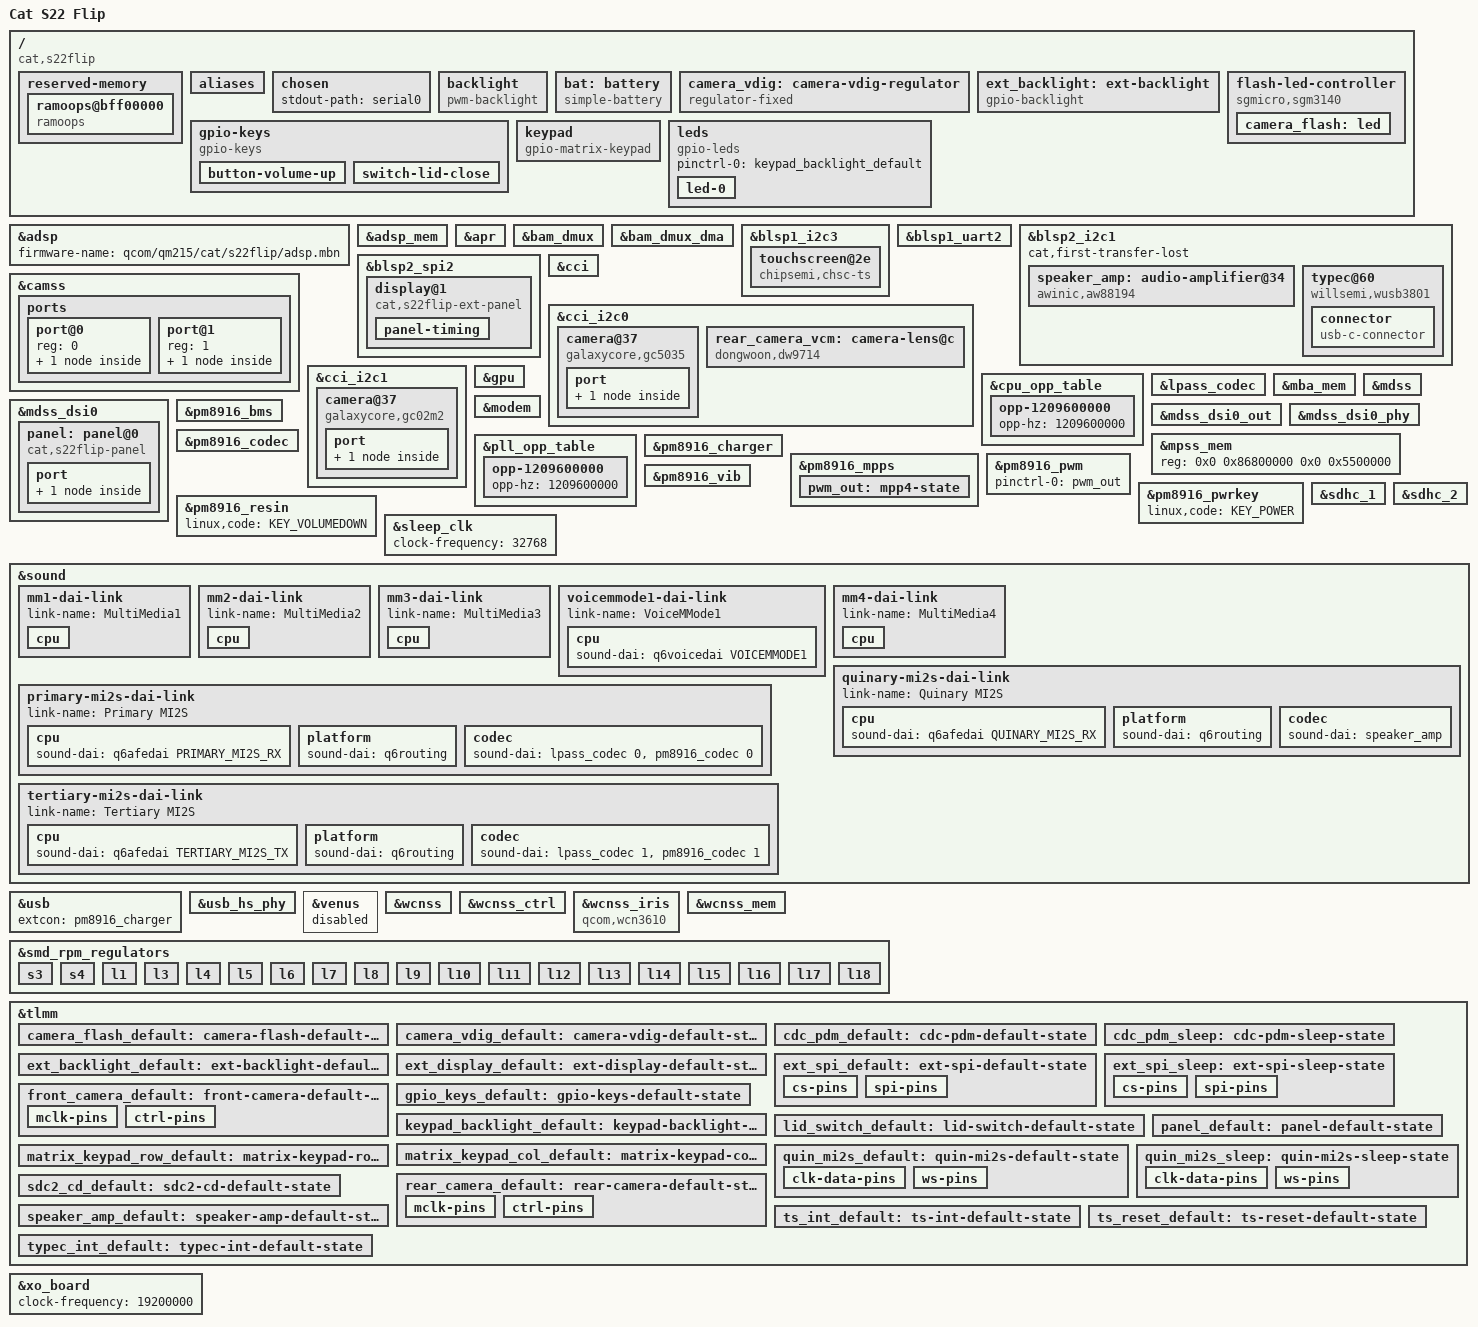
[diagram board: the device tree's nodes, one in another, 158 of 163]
// SPDX-License-Identifier: GPL-2.0-only
/*
 * Cat S22 Flip (QM215 + PM8916)
 *
 * Values marked "stock" come from the vendor device tree as running on
 * firmware LTE_S02113.11_N_S22Flip_0.030.03 (board id 12, dtbo 27).
 */

/dts-v1/;

#include "qm215-pm8916.dtsi"

#include <dt-bindings/gpio/gpio.h>
#include <dt-bindings/input/input.h>
#include <dt-bindings/interrupt-controller/irq.h>
#include <dt-bindings/leds/common.h>
#include <dt-bindings/pinctrl/qcom,pmic-mpp.h>
#include <dt-bindings/sound/qcom,q6voice.h>

/ {
	model = "Cat S22 Flip";
	compatible = "cat,s22flip", "qcom,qm215", "qcom,msm8917";
	chassis-type = "handset";

	reserved-memory {
		/*
		 * The kernel log survives a warm reset here (pstore):
		 * /sys/fs/pstore after the next boot. High in RAM, away
		 * from where the bootloaders load anything.
		 */
		ramoops@bff00000 {
			compatible = "ramoops";
			reg = <0x0 0xbff00000 0x0 0x100000>;
			record-size = <0x20000>;
			console-size = <0x40000>;
			pmsg-size = <0x20000>;
		};
	};

	aliases {
		mmc0 = &sdhc_1;
		mmc1 = &sdhc_2;
		serial0 = &blsp1_uart2;
	};

	chosen {
		stdout-path = "serial0";
	};

	/* Main display backlight: PM8916 LPG on MPP4 (stock: bl_ctrl_pwm, bank 0) */
	backlight: backlight {
		compatible = "pwm-backlight";
		pwms = <&pm8916_pwm 0 100000>;

		brightness-levels = <0 255>;
		num-interpolated-steps = <255>;
		default-brightness-level = <128>;
	};

	/* Stock battery profile "Q2805": 2000 mAh, OCV table at 25 C */
	bat: battery {
		compatible = "simple-battery";
		voltage-min-design-microvolt = <3400000>;
		/* Stock charger vddmax; the cell profile allows up to 4.35 V */
		voltage-max-design-microvolt = <4325000>;
		charge-full-design-microamp-hours = <2000000>;
		charge-term-current-microamp = <90000>;

		ocv-capacity-celsius = <25>;
		ocv-capacity-table-0 = <4318000 100>, <4246000 95>,
			<4190000 90>, <4136000 85>, <4084000 80>, <4038000 75>,
			<3982000 70>, <3952000 65>, <3912000 60>, <3866000 55>,
			<3834000 50>, <3812000 45>, <3795000 40>, <3782000 35>,
			<3772000 30>, <3763000 25>, <3756000 20>, <3739000 16>,
			<3732000 13>, <3725000 11>, <3718000 10>, <3686000 9>,
			<3684000 8>, <3682000 7>, <3676000 6>, <3654000 5>,
			<3610000 4>, <3549000 3>, <3470000 2>, <3345000 1>,
			<3000000 0>;
	};

	/*
	 * Outer display backlight. Stock drives it with a pulse-count protocol
	 * ("bl_gpio_pulse"); plain on/off is enough for now.
	 */
	/* 1.2 V for both cameras' digital cores, enabled by GPIO 25 */
	camera_vdig: camera-vdig-regulator {
		compatible = "regulator-fixed";
		regulator-name = "camera_vdig";
		regulator-min-microvolt = <1200000>;
		regulator-max-microvolt = <1200000>;
		gpio = <&tlmm 25 GPIO_ACTIVE_HIGH>;
		enable-active-high;

		pinctrl-0 = <&camera_vdig_default>;
		pinctrl-names = "default";
	};

	ext_backlight: ext-backlight {
		compatible = "gpio-backlight";
		gpios = <&tlmm 12 GPIO_ACTIVE_HIGH>;
		default-on;

		pinctrl-0 = <&ext_backlight_default>;
		pinctrl-names = "default";
	};

	/* Rear camera flash: stock "qm215-gpio-flash", enable 33, flash 34 */
	flash-led-controller {
		compatible = "sgmicro,sgm3140";
		enable-gpios = <&tlmm 33 GPIO_ACTIVE_HIGH>;
		flash-gpios = <&tlmm 34 GPIO_ACTIVE_HIGH>;

		pinctrl-0 = <&camera_flash_default>;
		pinctrl-names = "default";

		camera_flash: led {
			function = LED_FUNCTION_FLASH;
			color = <LED_COLOR_ID_WHITE>;
			flash-max-timeout-us = <250000>;
		};
	};

	gpio-keys {
		compatible = "gpio-keys";

		pinctrl-0 = <&gpio_keys_default>, <&lid_switch_default>;
		pinctrl-names = "default";

		label = "GPIO Buttons";

		button-volume-up {
			label = "Volume Up";
			gpios = <&tlmm 91 GPIO_ACTIVE_LOW>;
			linux,code = <KEY_VOLUMEUP>;
			debounce-interval = <15>;
			wakeup-source;
		};

		switch-lid-close {
			label = "Lid";
			gpios = <&tlmm 44 GPIO_ACTIVE_LOW>;
			linux,input-type = <EV_SW>;
			linux,code = <SW_LID>;
			wakeup-source;
		};
	};

	/*
	 * Stock scans this matrix active-high (no gpio-activelow): columns are
	 * driven high and a pressed key pulls its row high, so rows need
	 * pull-downs. Keycodes are the stock ones.
	 *
	 * Stock debounces for only 3 ms, but the domes chatter for up to ~35 ms
	 * after first contact (measured), producing double presses.
	 */
	keypad {
		compatible = "gpio-matrix-keypad";

		pinctrl-0 = <&matrix_keypad_row_default>, <&matrix_keypad_col_default>;
		pinctrl-names = "default";

		debounce-delay-ms = <30>;
		col-scan-delay-us = <5>;
		wakeup-source;

		row-gpios = <&tlmm 126 GPIO_ACTIVE_HIGH>,
			    <&tlmm 127 GPIO_ACTIVE_HIGH>,
			    <&tlmm 45 GPIO_ACTIVE_HIGH>,
			    <&tlmm 97 GPIO_ACTIVE_HIGH>,
			    <&tlmm 62 GPIO_ACTIVE_HIGH>;

		col-gpios = <&tlmm 96 GPIO_ACTIVE_HIGH>,
			    <&tlmm 99 GPIO_ACTIVE_HIGH>,
			    <&tlmm 90 GPIO_ACTIVE_HIGH>,
			    <&tlmm 89 GPIO_ACTIVE_HIGH>,
			    <&tlmm 129 GPIO_ACTIVE_HIGH>;

		linux,keymap = <
			MATRIX_KEY(0, 0, KEY_PHONE)
			MATRIX_KEY(0, 1, KEY_3)
			MATRIX_KEY(0, 2, KEY_6)
			MATRIX_KEY(0, 3, KEY_9)
			MATRIX_KEY(0, 4, KEY_NUMERIC_POUND)

			MATRIX_KEY(1, 0, KEY_LEFT)
			MATRIX_KEY(1, 1, KEY_2)
			MATRIX_KEY(1, 2, KEY_5)
			MATRIX_KEY(1, 3, KEY_8)
			MATRIX_KEY(1, 4, KEY_0)

			MATRIX_KEY(2, 0, KEY_MICMUTE)
			MATRIX_KEY(2, 1, KEY_1)
			MATRIX_KEY(2, 2, KEY_4)
			MATRIX_KEY(2, 3, KEY_7)
			MATRIX_KEY(2, 4, KEY_NUMERIC_STAR)

			MATRIX_KEY(3, 0, KEY_ENTER)
			MATRIX_KEY(3, 1, KEY_RIGHT)
			MATRIX_KEY(3, 2, KEY_BACKSPACE)
			MATRIX_KEY(3, 3, KEY_UP)
			MATRIX_KEY(3, 4, KEY_DOWN)

			MATRIX_KEY(4, 0, KEY_BACK)
			MATRIX_KEY(4, 1, KEY_APPSELECT)
			MATRIX_KEY(4, 2, KEY_HOMEPAGE)
			MATRIX_KEY(4, 3, KEY_NUMERIC_B)
			MATRIX_KEY(4, 4, KEY_NUMERIC_A)
		>;
	};

	leds {
		compatible = "gpio-leds";

		pinctrl-0 = <&keypad_backlight_default>;
		pinctrl-names = "default";

		led-0 {
			function = LED_FUNCTION_KBD_BACKLIGHT;
			color = <LED_COLOR_ID_WHITE>;
			gpios = <&tlmm 130 GPIO_ACTIVE_HIGH>;
			default-state = "off";
		};
	};
};

&adsp {
	firmware-name = "qcom/qm215/cat/s22flip/adsp.mbn";
	status = "okay";
};

&adsp_mem {
	status = "okay";
};

&apr {
	status = "okay";
};

&bam_dmux {
	status = "okay";
};

&bam_dmux_dma {
	status = "okay";
};

&blsp1_i2c3 {
	status = "okay";

	/* Main display touchscreen; vdd L17 is shared with the main panel */
	touchscreen@2e {
		compatible = "chipsemi,chsc-ts";
		reg = <0x2e>;
		interrupts-extended = <&tlmm 65 IRQ_TYPE_EDGE_FALLING>;
		reset-gpios = <&tlmm 64 GPIO_ACTIVE_LOW>;
		vdd-supply = <&pm8916_l17>;
		vio-supply = <&pm8916_l5>;
		touchscreen-size-x = <480>;
		touchscreen-size-y = <640>;

		pinctrl-0 = <&ts_int_default>, <&ts_reset_default>;
		pinctrl-names = "default";
	};
};

&blsp1_uart2 {
	status = "okay";
};

&blsp2_i2c1 {
	/* The first transfer after boot is NACKed; see i2c-qup */
	cat,first-transfer-lost;

	status = "okay";

	speaker_amp: audio-amplifier@34 {
		compatible = "awinic,aw88194";
		reg = <0x34>;
		reset-gpios = <&tlmm 66 GPIO_ACTIVE_LOW>;
		firmware-name = "qcom/qm215/cat/s22flip/aw881xx_acf.bin";
		sound-name-prefix = "Speaker";
		#sound-dai-cells = <0>;

		pinctrl-0 = <&speaker_amp_default>;
		pinctrl-names = "default";
	};

	typec@60 {
		compatible = "willsemi,wusb3801";
		reg = <0x60>;
		interrupts-extended = <&tlmm 17 IRQ_TYPE_LEVEL_LOW>;

		pinctrl-0 = <&typec_int_default>;
		pinctrl-names = "default";

		connector {
			compatible = "usb-c-connector";
			label = "USB-C";
			/* Sink only until the OTG VBUS supply is identified */
			power-role = "sink";
			data-role = "device";
			typec-power-opmode = "default";
			pd-disable;
		};
	};
};

&blsp2_spi2 {
	/* Only CS1 (GPIO 22) is wired; leave CS0 (GPIO 47) untouched */
	pinctrl-0 = <&ext_spi_default>;
	pinctrl-1 = <&ext_spi_sleep>;
	pinctrl-names = "default", "sleep";

	status = "okay";

	/*
	 * 128x128 outer display, ST7735S-class controller (stock calls it
	 * "st7789v2 qvga"). Init sequence converted from the stock
	 * qcom,mdss-spi-on-command; the visible area starts at column 2, row 3.
	 */
	display@1 {
		compatible = "cat,s22flip-ext-panel", "panel-mipi-dbi-spi";
		reg = <1>;
		spi-max-frequency = <50000000>;

		/* mipi-dbi treats reset as "1 = running"; the line itself is active low */
		reset-gpios = <&tlmm 125 GPIO_ACTIVE_HIGH>;
		dc-gpios = <&tlmm 68 GPIO_ACTIVE_HIGH>;

		power-supply = <&pm8916_l17>;
		io-supply = <&pm8916_l6>;
		backlight = <&ext_backlight>;

		/* Estimated (1.44-inch class square panel), not measured */
		width-mm = <26>;
		height-mm = <26>;

		pinctrl-0 = <&ext_display_default>;
		pinctrl-names = "default";

		panel-timing {
			hactive = <128>;
			vactive = <128>;
			hback-porch = <2>;
			vback-porch = <3>;
			hfront-porch = <0>;
			vfront-porch = <0>;
			hsync-len = <0>;
			vsync-len = <0>;
			clock-frequency = <(130 * 131 * 30)>;
		};
	};
};

&camss {
	status = "okay";

	ports {
		port@0 {
			reg = <0>;

			/* Lanes as on the Nokia 2780 (same SoC and sensor) */
			csiphy0_ep: endpoint {
				clock-lanes = <7>;
				data-lanes = <0 1>;
				link-frequencies = /bits/ 64 <438000000>;
				remote-endpoint = <&rear_camera_ep>;
			};
		};

		port@1 {
			reg = <1>;

			/* One lane (stock: lane mask 0x3) */
			csiphy1_ep: endpoint {
				clock-lanes = <7>;
				data-lanes = <0>;
				link-frequencies = /bits/ 64 <336000000>;
				remote-endpoint = <&front_camera_ep>;
			};
		};
	};
};

&cci {
	status = "okay";
};

&cci_i2c0 {
	/*
	 * Rear: GC5035, 5 MP, two lanes on CSIPHY0, mounted at 270 degrees.
	 * Strapped to 0x37 (stock: slave address 0x6e), not the Nokia's 0x3f.
	 */
	camera@37 {
		compatible = "galaxycore,gc5035";
		reg = <0x37>;

		resetb-gpios = <&tlmm 36 GPIO_ACTIVE_LOW>;
		pwdn-gpios = <&tlmm 35 GPIO_ACTIVE_LOW>;

		clocks = <&gcc GCC_CAMSS_MCLK0_CLK>;
		clock-names = "mclk";
		clock-frequency = <24000000>;

		iovdd-supply = <&pm8916_l6>;
		avdd28-supply = <&pm8916_l16>;
		dvdd12-supply = <&camera_vdig>;

		lens-focus = <&rear_camera_vcm>;
		flash-leds = <&camera_flash>;
		orientation = <1>;
		rotation = <270>;

		pinctrl-0 = <&rear_camera_default>;
		pinctrl-names = "default";

		port {
			rear_camera_ep: endpoint {
				data-lanes = <0 1>;
				link-frequencies = /bits/ 64 <438000000>;
				remote-endpoint = <&csiphy0_ep>;
			};
		};
	};

	rear_camera_vcm: camera-lens@c {
		compatible = "dongwoon,dw9714";
		reg = <0x0c>;
		vcc-supply = <&pm8916_l10>;
	};
};

&cci_i2c1 {
	/* Front: GC02M2, 2 MP, one lane on CSIPHY1 (stock: slave 0x6e) */
	camera@37 {
		compatible = "galaxycore,gc02m2";
		reg = <0x37>;

		reset-gpios = <&tlmm 40 GPIO_ACTIVE_LOW>;
		powerdown-gpios = <&tlmm 39 GPIO_ACTIVE_LOW>;

		clocks = <&gcc GCC_CAMSS_MCLK2_CLK>;

		dovdd-supply = <&pm8916_l6>;
		avdd-supply = <&pm8916_l16>;
		dvdd-supply = <&camera_vdig>;

		orientation = <0>;
		rotation = <270>;

		pinctrl-0 = <&front_camera_default>;
		pinctrl-names = "default";

		port {
			front_camera_ep: endpoint {
				data-lanes = <1>;
				link-frequencies = /bits/ 64 <336000000>;
				remote-endpoint = <&csiphy1_ep>;
			};
		};
	};
};

&cpu_opp_table {
	/*
	 * This QM215 is fused as speed bin 2 (stock: 960, 1094.4, 1209.6 MHz).
	 * The msm8917 table has steps above that and no voltages to go with
	 * them, so match stock.
	 */
	/delete-node/ opp-1248000000;
	/delete-node/ opp-1401600000;

	opp-1209600000 {
		opp-hz = /bits/ 64 <1209600000>;
	};
};

&gpu {
	status = "okay";
};

&lpass_codec {
	status = "okay";
};

&mba_mem {
	status = "okay";
};

&mdss {
	status = "okay";
};

/* Stock gives the DSI "vdda" 1.744-1.904 V, i.e. L6, not L2 */
&mdss_dsi0 {
	vdda-supply = <&pm8916_l6>;
	vddio-supply = <&pm8916_l6>;

	panel: panel@0 {
		/* lk2nd replaces this with the detected panel, e.g. "cat,s22flip-st7701s" */
		compatible = "cat,s22flip-panel";
		reg = <0>;

		reset-gpios = <&tlmm 60 GPIO_ACTIVE_LOW>;

		vdd-supply = <&pm8916_l17>;
		vddio-supply = <&pm8916_l6>;

		backlight = <&backlight>;

		pinctrl-0 = <&panel_default>;
		pinctrl-names = "default";

		port {
			panel_in: endpoint {
				remote-endpoint = <&mdss_dsi0_out>;
			};
		};
	};
};

&mdss_dsi0_out {
	data-lanes = <0 1>;
	remote-endpoint = <&panel_in>;
};

&mdss_dsi0_phy {
	vddio-supply = <&pm8916_l6>;
	qcom,dsi-phy-regulator-ldo-mode;
};

&modem {
	firmware-name = "qcom/qm215/cat/s22flip/mba.mbn",
			"qcom/qm215/cat/s22flip/modem.mbn";
	status = "okay";
};

/* Stock modem_region: 0x86800000, size 0x5500000 */
&mpss_mem {
	reg = <0x0 0x86800000 0x0 0x5500000>;
	status = "okay";
};

&pll_opp_table {
	/* Speed bin 2; see cpu_opp_table */
	/delete-node/ opp-1248000000;
	/delete-node/ opp-1401600000;

	opp-1209600000 {
		opp-hz = /bits/ 64 <1209600000>;
	};
};

&pm8916_bms {
	monitored-battery = <&bat>;
	power-supplies = <&pm8916_charger>;
	status = "okay";
};

/* Stock: vddmax/vddsafe 4325 mV, ibatsafe 1400 mA */
&pm8916_charger {
	qcom,fast-charge-safe-current = <1400000>;
	qcom,fast-charge-safe-voltage = <4325000>;

	monitored-battery = <&bat>;

	status = "okay";
};

&pm8916_codec {
	vdd-cdc-io-supply = <&pm8916_l5>;
	vdd-cdc-tx-rx-cx-supply = <&pm8916_l5>;
	vdd-micbias-supply = <&pm8916_l13>;

	/* Stock: qcom,msm-mbhc-hphl-swh = <1>, qcom,msm-mbhc-gnd-swh = <1> */
	qcom,hphl-jack-type-normally-open;
	qcom,gnd-jack-type-normally-open;
	qcom,micbias1-ext-cap;
	qcom,mbhc-vthreshold-low = <75 150 225 450 500>;
	qcom,mbhc-vthreshold-high = <75 150 225 450 500>;

	status = "okay";
};

&pm8916_mpps {
	/*
	 * The LPG reaches MPP4 over DTEST2 on this board, not DTEST1 as on the
	 * msm8916 reference designs: the bootloader leaves MODE_CTL at 0x1a.
	 */
	pwm_out: mpp4-state {
		pins = "mpp4";
		function = "digital";
		power-source = <PM8916_MPP_VPH>;
		output-low;
		qcom,dtest = <2>;
	};
};

&pm8916_pwm {
	pinctrl-0 = <&pwm_out>;
	pinctrl-names = "default";

	status = "okay";
};

&pm8916_pwrkey {
	linux,code = <KEY_POWER>;
};

&pm8916_resin {
	linux,code = <KEY_VOLUMEDOWN>;
	status = "okay";
};

&pm8916_vib {
	status = "okay";
};

&sdhc_1 {
	status = "okay";
};

&sdhc_2 {
	pinctrl-0 = <&sdc2_default &sdc2_cd_default>;
	pinctrl-1 = <&sdc2_sleep &sdc2_cd_default>;
	pinctrl-names = "default", "sleep";

	cd-gpios = <&tlmm 67 GPIO_ACTIVE_HIGH>;

	status = "okay";
};

&sleep_clk {
	clock-frequency = <32768>;
};

&sound {
	model = "cat-s22flip";

	/*
	 * Stock: handset mic on AMIC1 and secondary mic on AMIC3, both on
	 * external MIC BIAS 1; headset mic on AMIC2 with MIC BIAS 2.
	 */
	audio-routing =
		"AMIC1", "MIC BIAS External1",
		"AMIC2", "MIC BIAS External2",
		"AMIC3", "MIC BIAS External1",
		"MM_DL1", "MultiMedia1 Playback",
		"MM_DL3", "MultiMedia3 Playback",
		"MM_DL4", "MultiMedia4 Playback",
		"MultiMedia2 Capture", "MM_UL2";

	pinctrl-0 = <&cdc_pdm_default>, <&quin_mi2s_default>;
	pinctrl-1 = <&cdc_pdm_sleep>, <&quin_mi2s_sleep>;
	pinctrl-names = "default", "sleep";

	status = "okay";

	mm1-dai-link {
		link-name = "MultiMedia1";

		cpu {
			sound-dai = <&q6asmdai MSM_FRONTEND_DAI_MULTIMEDIA1>;
		};
	};

	mm2-dai-link {
		link-name = "MultiMedia2";

		cpu {
			sound-dai = <&q6asmdai MSM_FRONTEND_DAI_MULTIMEDIA2>;
		};
	};

	mm3-dai-link {
		link-name = "MultiMedia3";

		cpu {
			sound-dai = <&q6asmdai MSM_FRONTEND_DAI_MULTIMEDIA3>;
		};
	};

	/*
	 * Voice calls (VoLTE): the modem's voice session on the ADSP. Opening
	 * this hostless 8 kHz PCM starts the session; the audio itself flows
	 * modem -> ADSP -> codec. As on the Nokia 2780 (same SoC).
	 */
	voicemmode1-dai-link {
		link-name = "VoiceMMode1";

		cpu {
			sound-dai = <&q6voicedai VOICEMMODE1>;
		};
	};

	mm4-dai-link {
		link-name = "MultiMedia4";

		cpu {
			sound-dai = <&q6asmdai MSM_FRONTEND_DAI_MULTIMEDIA4>;
		};
	};

	primary-mi2s-dai-link {
		link-name = "Primary MI2S";

		cpu {
			sound-dai = <&q6afedai PRIMARY_MI2S_RX>;
		};

		platform {
			sound-dai = <&q6routing>;
		};

		codec {
			sound-dai = <&lpass_codec 0>, <&pm8916_codec 0>;
		};
	};

	quinary-mi2s-dai-link {
		link-name = "Quinary MI2S";

		cpu {
			sound-dai = <&q6afedai QUINARY_MI2S_RX>;
		};

		platform {
			sound-dai = <&q6routing>;
		};

		codec {
			sound-dai = <&speaker_amp>;
		};
	};

	tertiary-mi2s-dai-link {
		link-name = "Tertiary MI2S";

		cpu {
			sound-dai = <&q6afedai TERTIARY_MI2S_TX>;
		};

		platform {
			sound-dai = <&q6routing>;
		};

		codec {
			sound-dai = <&lpass_codec 1>, <&pm8916_codec 1>;
		};
	};
};

&usb {
	extcon = <&pm8916_charger>;
	status = "okay";
};

&usb_hs_phy {
	status = "okay";
};

/*
 * No Venus firmware or venus_mem carve-out yet, so its probe fails, and a
 * consumer that never probes keeps GCC's sync_state() pending forever.
 * Until then genpd keeps every GCC domain that was on at boot powered,
 * which is mdss_gdsc (the bootloader's splash): the display block never
 * power-collapses with the lid closed, and DPU registers survive a
 * display off/on (stale CTL flush and reset state on re-enable).
 */
&venus {
	status = "disabled";
};

&wcnss {
	firmware-name = "qcom/qm215/cat/s22flip/wcnss.mbn";
	status = "okay";
};

&wcnss_ctrl {
	firmware-name = "qcom/qm215/cat/s22flip/WCNSS_qcom_wlan_nv.bin";
};

/* dmesg "IRIS Reg: 91100004" -> chip id 0x9110 (WCN3610V1) */
&wcnss_iris {
	compatible = "qcom,wcn3610";
	status = "okay";
};

&wcnss_mem {
	status = "okay";
};

&smd_rpm_regulators {
	vdd_l1_l2_l3-supply = <&pm8916_s3>;
	vdd_l4_l5_l6-supply = <&pm8916_s4>;
	vdd_l7-supply = <&pm8916_s4>;

	s3 {
		regulator-min-microvolt = <1200000>;
		regulator-max-microvolt = <1200000>;
	};

	s4 {
		regulator-min-microvolt = <2050000>;
		regulator-max-microvolt = <2050000>;
	};

	l1 {
		regulator-min-microvolt = <968000>;
		regulator-max-microvolt = <1152000>;
	};

	l3 {
		regulator-min-microvolt = <1325000>;
		regulator-max-microvolt = <1325000>;
	};

	l4 {
		regulator-min-microvolt = <1744000>;
		regulator-max-microvolt = <1896000>;
	};

	l5 {
		regulator-min-microvolt = <1800000>;
		regulator-max-microvolt = <1800000>;
	};

	l6 {
		regulator-min-microvolt = <1800000>;
		regulator-max-microvolt = <1800000>;
	};

	l7 {
		regulator-min-microvolt = <1800000>;
		regulator-max-microvolt = <1800000>;
	};

	/* eMMC vcc */
	l8 {
		regulator-min-microvolt = <2900000>;
		regulator-max-microvolt = <2900000>;
	};

	/* WCN3610 vddpa */
	l9 {
		regulator-min-microvolt = <3300000>;
		regulator-max-microvolt = <3300000>;
	};

	l10 {
		regulator-min-microvolt = <2704000>;
		regulator-max-microvolt = <2850000>;
	};

	/* microSD vcc */
	l11 {
		regulator-min-microvolt = <2950000>;
		regulator-max-microvolt = <2950000>;
		regulator-system-load = <200000>;
		regulator-allow-set-load;
	};

	/* microSD vccq, 1.8 V for UHS */
	l12 {
		regulator-min-microvolt = <1800000>;
		regulator-max-microvolt = <2950000>;
	};

	l13 {
		regulator-min-microvolt = <3075000>;
		regulator-max-microvolt = <3075000>;
	};

	l14 {
		regulator-min-microvolt = <1800000>;
		regulator-max-microvolt = <3056000>;
	};

	l15 {
		regulator-min-microvolt = <1800000>;
		regulator-max-microvolt = <3056000>;
	};

	l16 {
		regulator-min-microvolt = <2800000>;
		regulator-max-microvolt = <2800000>;
	};

	/* Outer display vdd is 2.85 V on stock */
	l17 {
		regulator-min-microvolt = <2850000>;
		regulator-max-microvolt = <2850000>;
	};

	l18 {
		regulator-min-microvolt = <2600000>;
		regulator-max-microvolt = <2800000>;
	};
};

&tlmm {
	camera_flash_default: camera-flash-default-state {
		pins = "gpio33", "gpio34";
		function = "gpio";
		drive-strength = <2>;
		bias-disable;
	};

	camera_vdig_default: camera-vdig-default-state {
		pins = "gpio25";
		function = "gpio";
		drive-strength = <2>;
		bias-disable;
	};

	cdc_pdm_default: cdc-pdm-default-state {
		pins = "gpio69", "gpio70", "gpio71", "gpio72", "gpio73", "gpio74";
		function = "cdc_pdm0";
		drive-strength = <8>;
		bias-disable;
	};

	cdc_pdm_sleep: cdc-pdm-sleep-state {
		pins = "gpio69", "gpio70", "gpio71", "gpio72", "gpio73", "gpio74";
		function = "cdc_pdm0";
		drive-strength = <2>;
		bias-disable;
	};

	ext_backlight_default: ext-backlight-default-state {
		pins = "gpio12";
		function = "gpio";
		drive-strength = <2>;
		bias-disable;
	};

	ext_display_default: ext-display-default-state {
		pins = "gpio68", "gpio125";
		function = "gpio";
		drive-strength = <8>;
		bias-disable;
	};

	ext_spi_default: ext-spi-default-state {
		cs-pins {
			pins = "gpio22";
			function = "blsp_spi6";
			drive-strength = <16>;
			bias-disable;
		};

		spi-pins {
			pins = "gpio20", "gpio21", "gpio23";
			function = "blsp_spi6";
			drive-strength = <16>;
			bias-disable;
		};
	};

	ext_spi_sleep: ext-spi-sleep-state {
		cs-pins {
			pins = "gpio22";
			function = "gpio";
			drive-strength = <2>;
			bias-disable;
		};

		spi-pins {
			pins = "gpio20", "gpio21", "gpio23";
			function = "gpio";
			drive-strength = <2>;
			bias-pull-down;
		};
	};

	front_camera_default: front-camera-default-state {
		mclk-pins {
			pins = "gpio28";
			function = "cam_mclk";
			drive-strength = <2>;
			bias-disable;
		};

		ctrl-pins {
			pins = "gpio39", "gpio40";
			function = "gpio";
			drive-strength = <2>;
			bias-disable;
		};
	};

	gpio_keys_default: gpio-keys-default-state {
		pins = "gpio91";
		function = "gpio";
		drive-strength = <2>;
		bias-pull-up;
	};

	keypad_backlight_default: keypad-backlight-default-state {
		pins = "gpio130";
		function = "gpio";
		drive-strength = <2>;
		bias-disable;
	};

	lid_switch_default: lid-switch-default-state {
		pins = "gpio44";
		function = "gpio";
		drive-strength = <2>;
		bias-pull-up;
	};

	matrix_keypad_col_default: matrix-keypad-col-default-state {
		pins = "gpio96", "gpio99", "gpio90", "gpio89", "gpio129";
		function = "gpio";
		drive-strength = <2>;
		bias-disable;
	};

	matrix_keypad_row_default: matrix-keypad-row-default-state {
		pins = "gpio126", "gpio127", "gpio45", "gpio97", "gpio62";
		function = "gpio";
		drive-strength = <2>;
		bias-pull-down;
	};

	panel_default: panel-default-state {
		pins = "gpio60";
		function = "gpio";
		drive-strength = <8>;
		bias-disable;
	};

	/* Quinary MI2S goes out on the pri_mi2s pins (selected by quin-iomux) */
	quin_mi2s_default: quin-mi2s-default-state {
		clk-data-pins {
			pins = "gpio85", "gpio86", "gpio88";
			function = "pri_mi2s";
			drive-strength = <8>;
			bias-disable;
		};

		ws-pins {
			pins = "gpio87";
			function = "pri_mi2s_ws";
			drive-strength = <8>;
			bias-disable;
		};
	};

	quin_mi2s_sleep: quin-mi2s-sleep-state {
		clk-data-pins {
			pins = "gpio85", "gpio86", "gpio88";
			function = "pri_mi2s";
			drive-strength = <2>;
			bias-pull-down;
		};

		ws-pins {
			pins = "gpio87";
			function = "pri_mi2s_ws";
			drive-strength = <2>;
			bias-pull-down;
		};
	};

	rear_camera_default: rear-camera-default-state {
		mclk-pins {
			pins = "gpio26";
			function = "cam_mclk";
			drive-strength = <2>;
			bias-disable;
		};

		ctrl-pins {
			pins = "gpio35", "gpio36";
			function = "gpio";
			drive-strength = <2>;
			bias-disable;
		};
	};

	sdc2_cd_default: sdc2-cd-default-state {
		pins = "gpio67";
		function = "gpio";
		drive-strength = <2>;
		bias-pull-up;
	};

	speaker_amp_default: speaker-amp-default-state {
		pins = "gpio66";
		function = "gpio";
		drive-strength = <2>;
		bias-disable;
	};

	ts_int_default: ts-int-default-state {
		pins = "gpio65";
		function = "gpio";
		drive-strength = <8>;
		bias-pull-up;
	};

	ts_reset_default: ts-reset-default-state {
		pins = "gpio64";
		function = "gpio";
		drive-strength = <8>;
		bias-pull-up;
	};

	typec_int_default: typec-int-default-state {
		pins = "gpio17";
		function = "gpio";
		drive-strength = <2>;
		bias-pull-up;
	};
};

&xo_board {
	clock-frequency = <19200000>;
};
